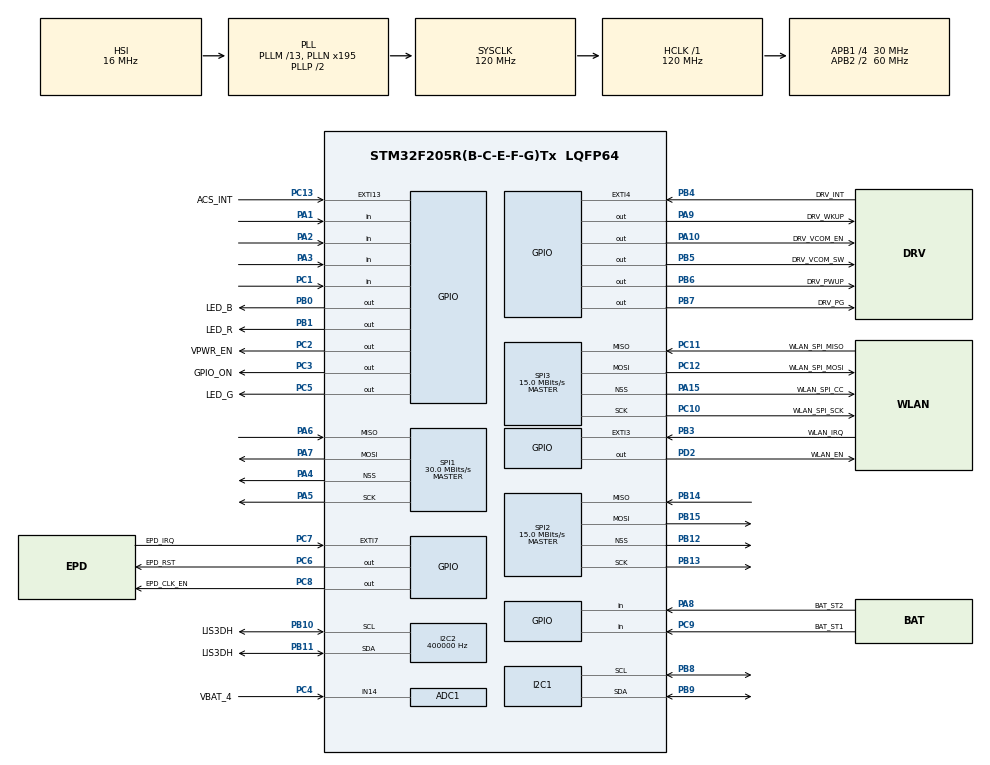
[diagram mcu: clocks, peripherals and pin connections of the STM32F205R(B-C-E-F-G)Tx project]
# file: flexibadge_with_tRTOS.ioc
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ADC1.Channel-4\#ChannelRegularConversion=ADC_CHANNEL_14
ADC1.NbrOfConversionFlag=1
ADC1.Rank-4\#ChannelRegularConversion=1
ADC1.SamplingTime-4\#ChannelRegularConversion=ADC_SAMPLETIME_3CYCLES
ADC1.master=1
Dma.Request0=SPI3_RX
Dma.Request1=SPI3_TX
Dma.SPI3_RX.0.Direction=DMA_PERIPH_TO_MEMORY
Dma.SPI3_RX.0.FIFOMode=DMA_FIFOMODE_DISABLE
Dma.SPI3_RX.0.Instance=DMA1_Stream0
Dma.SPI3_RX.0.MemDataAlignment=DMA_MDATAALIGN_BYTE
Dma.SPI3_RX.0.MemInc=DMA_MINC_ENABLE
Dma.SPI3_RX.0.Mode=DMA_NORMAL
Dma.SPI3_RX.0.PeriphDataAlignment=DMA_PDATAALIGN_BYTE
Dma.SPI3_RX.0.PeriphInc=DMA_PINC_DISABLE
Dma.SPI3_RX.0.Priority=DMA_PRIORITY_LOW
Dma.SPI3_TX.1.Direction=DMA_MEMORY_TO_PERIPH
Dma.SPI3_TX.1.FIFOMode=DMA_FIFOMODE_DISABLE
Dma.SPI3_TX.1.Instance=DMA1_Stream5
Dma.SPI3_TX.1.MemDataAlignment=DMA_MDATAALIGN_BYTE
Dma.SPI3_TX.1.MemInc=DMA_MINC_ENABLE
Dma.SPI3_TX.1.Mode=DMA_NORMAL
Dma.SPI3_TX.1.PeriphDataAlignment=DMA_PDATAALIGN_BYTE
Dma.SPI3_TX.1.PeriphInc=DMA_PINC_DISABLE
Dma.SPI3_TX.1.Priority=DMA_PRIORITY_LOW
FREERTOS.Tasks01=defaultTask,0,128,StartDefaultTask,Default,NULL,Dynamic,NULL,NULL;wifi,0,512,StartTask_wifi,Default,NULL,Dynamic,NULL,NULL
I2C2.ClockSpeed=400000
I2C2.I2C_Mode=I2C_Fast
Mcu.Family=STM32F2
Mcu.Name=STM32F205R(B-C-E-F-G)Tx
Mcu.Package=LQFP64
NVIC.DMA1_Stream0_IRQn=true\:5\:0\:false\:false\:true\:true
NVIC.DMA1_Stream5_IRQn=true\:5\:0\:false\:false\:true\:true
NVIC.EXTI15_10_IRQn=true\:5\:0\:false\:false\:true\:true
NVIC.EXTI3_IRQn=true\:5\:0\:false\:false\:true\:true
NVIC.I2C2_EV_IRQn=true\:5\:0\:false\:false\:true\:true
NVIC.PriorityGroup=NVIC_PRIORITYGROUP_4
NVIC.SPI1_IRQn=true\:5\:0\:false\:false\:true\:true
NVIC.TIM8_UP_TIM13_IRQn=true\:0\:0\:false\:false\:true\:false
NVIC.TimeBase=TIM8_UP_TIM13_IRQn
NVIC.TimeBaseIP=TIM8
PA0-WKUP.Mode=SYS_WakeUp0
PA0-WKUP.Signal=SYS_WKUP
PA1.Signal=GPIO_Input
PA10.GPIO_Label=DRV_VCOM_EN
PA10.Signal=GPIO_Output
PA13.Mode=Serial_Wire
PA13.Signal=SYS_JTMS-SWDIO
PA14.Mode=Serial_Wire
PA14.Signal=SYS_JTCK-SWCLK
PA15.GPIO_Label=WLAN_SPI_CC
PA15.Mode=NSS_Signal_Hard_Output
PA15.Signal=SPI3_NSS
PA2.Signal=GPIO_Input
PA3.Signal=GPIO_Input
PA4.Mode=NSS_Signal_Hard_Output
PA4.Signal=SPI1_NSS
PA5.Mode=Full_Duplex_Master
PA5.Signal=SPI1_SCK
PA6.Mode=Full_Duplex_Master
PA6.Signal=SPI1_MISO
PA7.Mode=Full_Duplex_Master
PA7.Signal=SPI1_MOSI
PA8.GPIO_Label=BAT_ST2
PA8.Signal=GPIO_Input
PA9.GPIO_Label=DRV_WKUP
PA9.Signal=GPIO_Output
PB0.GPIO_Label=LED_B
PB0.PinState=GPIO_PIN_SET
PB0.Signal=GPIO_Output
PB1.GPIO_Label=LED_R
PB1.PinState=GPIO_PIN_SET
PB1.Signal=GPIO_Output
PB10.GPIO_Label=LIS3DH
PB10.Mode=I2C
PB10.Signal=I2C2_SCL
PB11.GPIO_Label=LIS3DH
PB11.Mode=I2C
PB11.Signal=I2C2_SDA
PB12.Mode=NSS_Signal_Hard_Output
PB12.Signal=SPI2_NSS
PB13.Mode=Full_Duplex_Master
PB13.Signal=SPI2_SCK
PB14.Mode=Full_Duplex_Master
PB14.Signal=SPI2_MISO
PB15.Mode=Full_Duplex_Master
PB15.Signal=SPI2_MOSI
PB3.GPIO_Label=WLAN_IRQ
PB3.Signal=GPXTI3
PB4.GPIO_Label=DRV_INT
PB4.Signal=GPXTI4
PB5.GPIO_Label=DRV_VCOM_SW
PB5.Signal=GPIO_Output
PB6.GPIO_Label=DRV_PWUP
PB6.Signal=GPIO_Output
PB7.GPIO_Label=DRV_PG
PB7.Signal=GPIO_Output
PB8.Mode=I2C
PB8.Signal=I2C1_SCL
PB9.Mode=I2C
PB9.Signal=I2C1_SDA
PC1.Signal=GPIO_Input
PC10.GPIO_Label=WLAN_SPI_SCK
PC10.Mode=Full_Duplex_Master
PC10.Signal=SPI3_SCK
PC11.GPIO_Label=WLAN_SPI_MISO
PC11.Mode=Full_Duplex_Master
PC11.Signal=SPI3_MISO
PC12.GPIO_Label=WLAN_SPI_MOSI
PC12.Mode=Full_Duplex_Master
PC12.Signal=SPI3_MOSI
PC13.GPIO_Label=ACS_INT
PC13.Signal=GPXTI13
PC14-OSC32_IN.Mode=LSE-External-Oscillator
PC14-OSC32_IN.Signal=RCC_OSC32_IN
PC15-OSC32_OUT.Mode=LSE-External-Oscillator
PC15-OSC32_OUT.Signal=RCC_OSC32_OUT
PC2.GPIO_Label=VPWR_EN
PC2.PinState=GPIO_PIN_SET
PC2.Signal=GPIO_Output
PC3.GPIO_Label=GPIO_ON
PC3.Signal=GPIO_Output
PC4.GPIO_Label=VBAT_4
PC4.Signal=ADCx_IN14
PC5.GPIO_Label=LED_G
PC5.PinState=GPIO_PIN_SET
PC5.Signal=GPIO_Output
PC6.GPIO_Label=EPD_RST
PC6.Signal=GPIO_Output
PC7.GPIO_Label=EPD_IRQ
PC7.Signal=GPXTI7
PC8.GPIO_Label=EPD_CLK_EN
PC8.Signal=GPIO_Output
PC9.GPIO_Label=BAT_ST1
PC9.Signal=GPIO_Input
PD2.GPIO_Label=WLAN_EN
PD2.Signal=GPIO_Output
PH0-OSC_IN.Mode=HSE-External-Oscillator
PH0-OSC_IN.Signal=RCC_OSC_IN
PH1-OSC_OUT.Mode=HSE-External-Oscillator
PH1-OSC_OUT.Signal=RCC_OSC_OUT
ProjectManager.HeapSize=0x200
ProjectManager.StackSize=0x400
ProjectManager.TargetToolchain=TrueSTUDIO
RCC.48MHZClocksFreq_Value=48000000
RCC.AHBFreq_Value=120000000
RCC.APB1CLKDivider=RCC_HCLK_DIV4
RCC.APB1Freq_Value=30000000
RCC.APB1TimFreq_Value=60000000
RCC.APB2CLKDivider=RCC_HCLK_DIV2
RCC.APB2Freq_Value=60000000
RCC.APB2TimFreq_Value=120000000
RCC.CortexFreq_Value=120000000
RCC.HCLKFreq_Value=120000000
RCC.HSE_VALUE=16000000
RCC.HSI_VALUE=16000000
RCC.PLLM=13
RCC.PLLN=195
RCC.PLLQ=5
RCC.RCC_RTC_Clock_Source=RCC_RTCCLKSOURCE_LSE
RCC.RCC_RTC_Clock_SourceVirtual=RCC_RTCCLKSOURCE_LSE
RCC.RCC_RTC_Clock_Source_FROM_HSE=RCC_RTCCLKSOURCE_HSE_DIV31
RCC.SYSCLKFreq_VALUE=120000000
RCC.SYSCLKSource=RCC_SYSCLKSOURCE_PLLCLK
RCC.VCOOutputFreq_Value=240000000
SH.ADCx_IN14.0=ADC1_IN14,IN14
SPI1.BaudRatePrescaler=SPI_BAUDRATEPRESCALER_2
SPI1.CalculateBaudRate=30.0 MBits/s
SPI1.Mode=SPI_MODE_MASTER
SPI1.VirtualNSS=VM_NSSHARD
SPI1.VirtualType=VM_MASTER
SPI2.BaudRatePrescaler=SPI_BAUDRATEPRESCALER_2
SPI2.CalculateBaudRate=15.0 MBits/s
SPI2.Mode=SPI_MODE_MASTER
SPI2.VirtualNSS=VM_NSSHARD
SPI2.VirtualType=VM_MASTER
SPI3.BaudRatePrescaler=SPI_BAUDRATEPRESCALER_2
SPI3.CalculateBaudRate=15.0 MBits/s
SPI3.Mode=SPI_MODE_MASTER
SPI3.VirtualNSS=VM_NSSHARD
SPI3.VirtualType=VM_MASTER
VP_FREERTOS_VS_ENABLE.Mode=Enabled
VP_RTC_VS_RTC_Activate.Mode=RTC_Enabled
VP_SYS_VS_tim8.Mode=TIM8
board=flexibadge_with_tRTOS

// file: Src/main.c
/**
  ******************************************************************************
  * File Name          : main.c
  * Description        : Main program body
  ******************************************************************************
  * This notice applies to any and all portions of this file
  * that are not between comment pairs USER CODE BEGIN and
  * USER CODE END. Other portions of this file, whether
  * inserted by the user or by software development tools
  * are owned by their respective copyright owners.
  *
  * Copyright (c) 2017 STMicroelectronics International N.V.
  * All rights reserved.
  *
  * Redistribution and use in source and binary forms, with or without
  * modification, are permitted, provided that the following conditions are met:
  *
  * 1. Redistribution of source code must retain the above copyright notice,
  *    this list of conditions and the following disclaimer.
  * 2. Redistributions in binary form must reproduce the above copyright notice,
  *    this list of conditions and the following disclaimer in the documentation
  *    and/or other materials provided with the distribution.
  * 3. Neither the name of STMicroelectronics nor the names of other
  *    contributors to this software may be used to endorse or promote products
  *    derived from this software without specific written permission.
  * 4. This software, including modifications and/or derivative works of this
  *    software, must execute solely and exclusively on microcontroller or
  *    microprocessor devices manufactured by or for STMicroelectronics.
  * 5. Redistribution and use of this software other than as permitted under
  *    this license is void and will automatically terminate your rights under
  *    this license.
  *
  * THIS SOFTWARE IS PROVIDED BY STMICROELECTRONICS AND CONTRIBUTORS "AS IS"
  * AND ANY EXPRESS, IMPLIED OR STATUTORY WARRANTIES, INCLUDING, BUT NOT
  * LIMITED TO, THE IMPLIED WARRANTIES OF MERCHANTABILITY, FITNESS FOR A
  * PARTICULAR PURPOSE AND NON-INFRINGEMENT OF THIRD PARTY INTELLECTUAL PROPERTY
  * RIGHTS ARE DISCLAIMED TO THE FULLEST EXTENT PERMITTED BY LAW. IN NO EVENT
  * SHALL STMICROELECTRONICS OR CONTRIBUTORS BE LIABLE FOR ANY DIRECT, INDIRECT,
  * INCIDENTAL, SPECIAL, EXEMPLARY, OR CONSEQUENTIAL DAMAGES (INCLUDING, BUT NOT
  * LIMITED TO, PROCUREMENT OF SUBSTITUTE GOODS OR SERVICES; LOSS OF USE, DATA,
  * OR PROFITS; OR BUSINESS INTERRUPTION) HOWEVER CAUSED AND ON ANY THEORY OF
  * LIABILITY, WHETHER IN CONTRACT, STRICT LIABILITY, OR TORT (INCLUDING
  * NEGLIGENCE OR OTHERWISE) ARISING IN ANY WAY OUT OF THE USE OF THIS SOFTWARE,
  * EVEN IF ADVISED OF THE POSSIBILITY OF SUCH DAMAGE.
  *
  ******************************************************************************
  */
#include "main.h"
#include "stm32f2xx_hal.h"
#include "cmsis_os.h"

ADC_HandleTypeDef hadc1;

I2C_HandleTypeDef hi2c1;
I2C_HandleTypeDef hi2c2;

RTC_HandleTypeDef hrtc;

SPI_HandleTypeDef hspi1;
SPI_HandleTypeDef hspi2;
SPI_HandleTypeDef hspi3;
DMA_HandleTypeDef hdma_spi3_rx;
DMA_HandleTypeDef hdma_spi3_tx;

osThreadId defaultTaskHandle;
osThreadId wifiHandle;

/* USER CODE BEGIN PV */
/* Private variables ---------------------------------------------------------*/

/* USER CODE END PV */

void SystemClock_Config(void);
static void MX_GPIO_Init(void);
static void MX_DMA_Init(void);
static void MX_SPI1_Init(void);
static void MX_I2C2_Init(void);
static void MX_SPI2_Init(void);
static void MX_SPI3_Init(void);
static void MX_I2C1_Init(void);
static void MX_RTC_Init(void);
static void MX_ADC1_Init(void);
void StartDefaultTask(void const * argument);
void StartTask_wifi(void const * argument);

/* USER CODE BEGIN PFP */
/* Private function prototypes -----------------------------------------------*/

/* USER CODE END PFP */

int main(void)
{

  /* MCU Configuration----------------------------------------------------------*/

  /* Reset of all peripherals, Initializes the Flash interface and the Systick. */
  HAL_Init();

  /* Configure the system clock */
  SystemClock_Config();

  /* Initialize all configured peripherals */
  MX_GPIO_Init();
  MX_DMA_Init();
  MX_SPI1_Init();
  MX_I2C2_Init();
  MX_SPI2_Init();
  MX_SPI3_Init();
  MX_I2C1_Init();
  MX_RTC_Init();
  MX_ADC1_Init();

  /* Create the thread(s) */
  /* definition and creation of defaultTask */
  osThreadDef(defaultTask, StartDefaultTask, osPriorityNormal, 0, 128);
  defaultTaskHandle = osThreadCreate(osThread(defaultTask), NULL);

  /* definition and creation of wifi */
  osThreadDef(wifi, StartTask_wifi, osPriorityNormal, 0, 512);
  wifiHandle = osThreadCreate(osThread(wifi), NULL);

  /* Start scheduler */
  osKernelStart();

  /* We should never get here as control is now taken by the scheduler */

  /* Infinite loop */
  while (1)
  {

  }

}

/** System Clock Configuration
*/
void SystemClock_Config(void)
{

  RCC_OscInitTypeDef RCC_OscInitStruct;
  RCC_ClkInitTypeDef RCC_ClkInitStruct;
  RCC_PeriphCLKInitTypeDef PeriphClkInitStruct;

    /**Initializes the CPU, AHB and APB busses clocks
    */
  RCC_OscInitStruct.OscillatorType = RCC_OSCILLATORTYPE_HSI|RCC_OSCILLATORTYPE_LSE;
  RCC_OscInitStruct.LSEState = RCC_LSE_ON;
  RCC_OscInitStruct.HSIState = RCC_HSI_ON;
  RCC_OscInitStruct.HSICalibrationValue = 16;
  RCC_OscInitStruct.PLL.PLLState = RCC_PLL_ON;
  RCC_OscInitStruct.PLL.PLLSource = RCC_PLLSOURCE_HSI;
  RCC_OscInitStruct.PLL.PLLM = 13;
  RCC_OscInitStruct.PLL.PLLN = 195;
  RCC_OscInitStruct.PLL.PLLP = RCC_PLLP_DIV2;
  RCC_OscInitStruct.PLL.PLLQ = 5;
  if (HAL_RCC_OscConfig(&RCC_OscInitStruct) != HAL_OK)
  {
    _Error_Handler(__FILE__, __LINE__);
  }

    /**Initializes the CPU, AHB and APB busses clocks
    */
  RCC_ClkInitStruct.ClockType = RCC_CLOCKTYPE_HCLK|RCC_CLOCKTYPE_SYSCLK
                              |RCC_CLOCKTYPE_PCLK1|RCC_CLOCKTYPE_PCLK2;
  RCC_ClkInitStruct.SYSCLKSource = RCC_SYSCLKSOURCE_PLLCLK;
  RCC_ClkInitStruct.AHBCLKDivider = RCC_SYSCLK_DIV1;
  RCC_ClkInitStruct.APB1CLKDivider = RCC_HCLK_DIV4;
  RCC_ClkInitStruct.APB2CLKDivider = RCC_HCLK_DIV2;

  if (HAL_RCC_ClockConfig(&RCC_ClkInitStruct, FLASH_LATENCY_3) != HAL_OK)
  {
    _Error_Handler(__FILE__, __LINE__);
  }

  PeriphClkInitStruct.PeriphClockSelection = RCC_PERIPHCLK_RTC;
  PeriphClkInitStruct.RTCClockSelection = RCC_RTCCLKSOURCE_LSE;
  if (HAL_RCCEx_PeriphCLKConfig(&PeriphClkInitStruct) != HAL_OK)
  {
    _Error_Handler(__FILE__, __LINE__);
  }

    /**Configure the Systick interrupt time
    */
  HAL_SYSTICK_Config(HAL_RCC_GetHCLKFreq()/1000);

    /**Configure the Systick
    */
  HAL_SYSTICK_CLKSourceConfig(SYSTICK_CLKSOURCE_HCLK);

  /* SysTick_IRQn interrupt configuration */
  HAL_NVIC_SetPriority(SysTick_IRQn, 15, 0);
}

/* ADC1 init function */
static void MX_ADC1_Init(void)
{

  ADC_ChannelConfTypeDef sConfig;

    /**Configure the global features of the ADC (Clock, Resolution, Data Alignment and number of conversion)
    */
  hadc1.Instance = ADC1;
  hadc1.Init.ClockPrescaler = ADC_CLOCK_SYNC_PCLK_DIV2;
  hadc1.Init.Resolution = ADC_RESOLUTION_12B;
  hadc1.Init.ScanConvMode = DISABLE;
  hadc1.Init.ContinuousConvMode = DISABLE;
  hadc1.Init.DiscontinuousConvMode = DISABLE;
  hadc1.Init.ExternalTrigConvEdge = ADC_EXTERNALTRIGCONVEDGE_NONE;
  hadc1.Init.ExternalTrigConv = ADC_SOFTWARE_START;
  hadc1.Init.DataAlign = ADC_DATAALIGN_RIGHT;
  hadc1.Init.NbrOfConversion = 1;
  hadc1.Init.DMAContinuousRequests = DISABLE;
  hadc1.Init.EOCSelection = ADC_EOC_SINGLE_CONV;
  if (HAL_ADC_Init(&hadc1) != HAL_OK)
  {
    _Error_Handler(__FILE__, __LINE__);
  }

    /**Configure for the selected ADC regular channel its corresponding rank in the sequencer and its sample time.
    */
  sConfig.Channel = ADC_CHANNEL_14;
  sConfig.Rank = 1;
  sConfig.SamplingTime = ADC_SAMPLETIME_3CYCLES;
  if (HAL_ADC_ConfigChannel(&hadc1, &sConfig) != HAL_OK)
  {
    _Error_Handler(__FILE__, __LINE__);
  }

}

/* I2C1 init function */
static void MX_I2C1_Init(void)
{

  hi2c1.Instance = I2C1;
  hi2c1.Init.ClockSpeed = 100000;
  hi2c1.Init.DutyCycle = I2C_DUTYCYCLE_2;
  hi2c1.Init.OwnAddress1 = 0;
  hi2c1.Init.AddressingMode = I2C_ADDRESSINGMODE_7BIT;
  hi2c1.Init.DualAddressMode = I2C_DUALADDRESS_DISABLE;
  hi2c1.Init.OwnAddress2 = 0;
  hi2c1.Init.GeneralCallMode = I2C_GENERALCALL_DISABLE;
  hi2c1.Init.NoStretchMode = I2C_NOSTRETCH_DISABLE;
  if (HAL_I2C_Init(&hi2c1) != HAL_OK)
  {
    _Error_Handler(__FILE__, __LINE__);
  }

}

/* I2C2 init function */
static void MX_I2C2_Init(void)
{

  hi2c2.Instance = I2C2;
  hi2c2.Init.ClockSpeed = 400000;
  hi2c2.Init.DutyCycle = I2C_DUTYCYCLE_2;
  hi2c2.Init.OwnAddress1 = 0;
  hi2c2.Init.AddressingMode = I2C_ADDRESSINGMODE_7BIT;
  hi2c2.Init.DualAddressMode = I2C_DUALADDRESS_DISABLE;
  hi2c2.Init.OwnAddress2 = 0;
  hi2c2.Init.GeneralCallMode = I2C_GENERALCALL_DISABLE;
  hi2c2.Init.NoStretchMode = I2C_NOSTRETCH_DISABLE;
  if (HAL_I2C_Init(&hi2c2) != HAL_OK)
  {
    _Error_Handler(__FILE__, __LINE__);
  }

}

/* RTC init function */
static void MX_RTC_Init(void)
{

    /**Initialize RTC Only
    */
  hrtc.Instance = RTC;
  hrtc.Init.HourFormat = RTC_HOURFORMAT_24;
  hrtc.Init.AsynchPrediv = 127;
  hrtc.Init.SynchPrediv = 255;
  hrtc.Init.OutPut = RTC_OUTPUT_DISABLE;
  hrtc.Init.OutPutPolarity = RTC_OUTPUT_POLARITY_HIGH;
  hrtc.Init.OutPutType = RTC_OUTPUT_TYPE_OPENDRAIN;
  if (HAL_RTC_Init(&hrtc) != HAL_OK)
  {
    _Error_Handler(__FILE__, __LINE__);
  }

}

/* SPI1 init function */
static void MX_SPI1_Init(void)
{

  hspi1.Instance = SPI1;
  hspi1.Init.Mode = SPI_MODE_MASTER;
  hspi1.Init.Direction = SPI_DIRECTION_2LINES;
  hspi1.Init.DataSize = SPI_DATASIZE_8BIT;
  hspi1.Init.CLKPolarity = SPI_POLARITY_LOW;
  hspi1.Init.CLKPhase = SPI_PHASE_1EDGE;
  hspi1.Init.NSS = SPI_NSS_HARD_OUTPUT;
  hspi1.Init.BaudRatePrescaler = SPI_BAUDRATEPRESCALER_2;
  hspi1.Init.FirstBit = SPI_FIRSTBIT_MSB;
  hspi1.Init.TIMode = SPI_TIMODE_DISABLE;
  hspi1.Init.CRCCalculation = SPI_CRCCALCULATION_DISABLE;
  hspi1.Init.CRCPolynomial = 10;
  if (HAL_SPI_Init(&hspi1) != HAL_OK)
  {
    _Error_Handler(__FILE__, __LINE__);
  }

}

/* SPI2 init function */
static void MX_SPI2_Init(void)
{

  hspi2.Instance = SPI2;
  hspi2.Init.Mode = SPI_MODE_MASTER;
  hspi2.Init.Direction = SPI_DIRECTION_2LINES;
  hspi2.Init.DataSize = SPI_DATASIZE_8BIT;
  hspi2.Init.CLKPolarity = SPI_POLARITY_LOW;
  hspi2.Init.CLKPhase = SPI_PHASE_1EDGE;
  hspi2.Init.NSS = SPI_NSS_HARD_OUTPUT;
  hspi2.Init.BaudRatePrescaler = SPI_BAUDRATEPRESCALER_2;
  hspi2.Init.FirstBit = SPI_FIRSTBIT_MSB;
  hspi2.Init.TIMode = SPI_TIMODE_DISABLE;
  hspi2.Init.CRCCalculation = SPI_CRCCALCULATION_DISABLE;
  hspi2.Init.CRCPolynomial = 10;
  if (HAL_SPI_Init(&hspi2) != HAL_OK)
  {
    _Error_Handler(__FILE__, __LINE__);
  }

}

/* SPI3 init function */
static void MX_SPI3_Init(void)
{

  hspi3.Instance = SPI3;
  hspi3.Init.Mode = SPI_MODE_MASTER;
  hspi3.Init.Direction = SPI_DIRECTION_2LINES;
  hspi3.Init.DataSize = SPI_DATASIZE_8BIT;
  hspi3.Init.CLKPolarity = SPI_POLARITY_LOW;
  hspi3.Init.CLKPhase = SPI_PHASE_1EDGE;
  hspi3.Init.NSS = SPI_NSS_HARD_OUTPUT;
  hspi3.Init.BaudRatePrescaler = SPI_BAUDRATEPRESCALER_2;
  hspi3.Init.FirstBit = SPI_FIRSTBIT_MSB;
  hspi3.Init.TIMode = SPI_TIMODE_DISABLE;
  hspi3.Init.CRCCalculation = SPI_CRCCALCULATION_DISABLE;
  hspi3.Init.CRCPolynomial = 10;
  if (HAL_SPI_Init(&hspi3) != HAL_OK)
  {
    _Error_Handler(__FILE__, __LINE__);
  }

}

static void MX_DMA_Init(void)
{
  /* DMA controller clock enable */
  __HAL_RCC_DMA1_CLK_ENABLE();

  /* DMA interrupt init */
  /* DMA1_Stream0_IRQn interrupt configuration */
  HAL_NVIC_SetPriority(DMA1_Stream0_IRQn, 5, 0);
  HAL_NVIC_EnableIRQ(DMA1_Stream0_IRQn);
  /* DMA1_Stream5_IRQn interrupt configuration */
  HAL_NVIC_SetPriority(DMA1_Stream5_IRQn, 5, 0);
  HAL_NVIC_EnableIRQ(DMA1_Stream5_IRQn);

}

/** Configure pins as
        * Analog
        * Input
        * Output
        * EVENT_OUT
        * EXTI
*/
static void MX_GPIO_Init(void)
{

  GPIO_InitTypeDef GPIO_InitStruct;

  /* GPIO Ports Clock Enable */
  __HAL_RCC_GPIOC_CLK_ENABLE();
  __HAL_RCC_GPIOH_CLK_ENABLE();
  __HAL_RCC_GPIOA_CLK_ENABLE();
  __HAL_RCC_GPIOB_CLK_ENABLE();
  __HAL_RCC_GPIOD_CLK_ENABLE();

  /*Configure GPIO pin Output Level */
  HAL_GPIO_WritePin(GPIOC, VPWR_EN_Pin|LED_G_Pin, GPIO_PIN_SET);

  /*Configure GPIO pin Output Level */
  HAL_GPIO_WritePin(GPIOC, GPIO_ON_Pin|EPD_RST_Pin|EPD_CLK_EN_Pin, GPIO_PIN_RESET);

  /*Configure GPIO pin Output Level */
  HAL_GPIO_WritePin(GPIOB, LED_B_Pin|LED_R_Pin, GPIO_PIN_SET);

  /*Configure GPIO pin Output Level */
  HAL_GPIO_WritePin(GPIOA, DRV_WKUP_Pin|DRV_VCOM_EN_Pin, GPIO_PIN_RESET);

  /*Configure GPIO pin Output Level */
  HAL_GPIO_WritePin(WLAN_EN_GPIO_Port, WLAN_EN_Pin, GPIO_PIN_RESET);

  /*Configure GPIO pin Output Level */
  HAL_GPIO_WritePin(GPIOB, DRV_VCOM_SW_Pin|DRV_PWUP_Pin|DRV_PG_Pin, GPIO_PIN_RESET);

  /*Configure GPIO pins : ACS_INT_Pin EPD_IRQ_Pin */
  GPIO_InitStruct.Pin = ACS_INT_Pin|EPD_IRQ_Pin;
  GPIO_InitStruct.Mode = GPIO_MODE_IT_RISING;
  GPIO_InitStruct.Pull = GPIO_NOPULL;
  HAL_GPIO_Init(GPIOC, &GPIO_InitStruct);

  /*Configure GPIO pins : PC1 BAT_ST1_Pin */
  GPIO_InitStruct.Pin = GPIO_PIN_1|BAT_ST1_Pin;
  GPIO_InitStruct.Mode = GPIO_MODE_INPUT;
  GPIO_InitStruct.Pull = GPIO_NOPULL;
  HAL_GPIO_Init(GPIOC, &GPIO_InitStruct);

  /*Configure GPIO pins : VPWR_EN_Pin GPIO_ON_Pin LED_G_Pin EPD_RST_Pin
                           EPD_CLK_EN_Pin */
  GPIO_InitStruct.Pin = VPWR_EN_Pin|GPIO_ON_Pin|LED_G_Pin|EPD_RST_Pin
                          |EPD_CLK_EN_Pin;
  GPIO_InitStruct.Mode = GPIO_MODE_OUTPUT_PP;
  GPIO_InitStruct.Pull = GPIO_NOPULL;
  GPIO_InitStruct.Speed = GPIO_SPEED_FREQ_LOW;
  HAL_GPIO_Init(GPIOC, &GPIO_InitStruct);

  /*Configure GPIO pins : PA1 PA2 PA3 BAT_ST2_Pin */
  GPIO_InitStruct.Pin = GPIO_PIN_1|GPIO_PIN_2|GPIO_PIN_3|BAT_ST2_Pin;
  GPIO_InitStruct.Mode = GPIO_MODE_INPUT;
  GPIO_InitStruct.Pull = GPIO_NOPULL;
  HAL_GPIO_Init(GPIOA, &GPIO_InitStruct);

  /*Configure GPIO pins : LED_B_Pin LED_R_Pin DRV_VCOM_SW_Pin DRV_PWUP_Pin
                           DRV_PG_Pin */
  GPIO_InitStruct.Pin = LED_B_Pin|LED_R_Pin|DRV_VCOM_SW_Pin|DRV_PWUP_Pin
                          |DRV_PG_Pin;
  GPIO_InitStruct.Mode = GPIO_MODE_OUTPUT_PP;
  GPIO_InitStruct.Pull = GPIO_NOPULL;
  GPIO_InitStruct.Speed = GPIO_SPEED_FREQ_LOW;
  HAL_GPIO_Init(GPIOB, &GPIO_InitStruct);

  /*Configure GPIO pins : DRV_WKUP_Pin DRV_VCOM_EN_Pin */
  GPIO_InitStruct.Pin = DRV_WKUP_Pin|DRV_VCOM_EN_Pin;
  GPIO_InitStruct.Mode = GPIO_MODE_OUTPUT_PP;
  GPIO_InitStruct.Pull = GPIO_NOPULL;
  GPIO_InitStruct.Speed = GPIO_SPEED_FREQ_LOW;
  HAL_GPIO_Init(GPIOA, &GPIO_InitStruct);

  /*Configure GPIO pin : WLAN_EN_Pin */
  GPIO_InitStruct.Pin = WLAN_EN_Pin;
  GPIO_InitStruct.Mode = GPIO_MODE_OUTPUT_PP;
  GPIO_InitStruct.Pull = GPIO_NOPULL;
  GPIO_InitStruct.Speed = GPIO_SPEED_FREQ_LOW;
  HAL_GPIO_Init(WLAN_EN_GPIO_Port, &GPIO_InitStruct);

  /*Configure GPIO pins : WLAN_IRQ_Pin DRV_INT_Pin */
  GPIO_InitStruct.Pin = WLAN_IRQ_Pin|DRV_INT_Pin;
  GPIO_InitStruct.Mode = GPIO_MODE_IT_RISING;
  GPIO_InitStruct.Pull = GPIO_NOPULL;
  HAL_GPIO_Init(GPIOB, &GPIO_InitStruct);

  /* EXTI interrupt init*/
  HAL_NVIC_SetPriority(EXTI3_IRQn, 5, 0);
  HAL_NVIC_EnableIRQ(EXTI3_IRQn);

  HAL_NVIC_SetPriority(EXTI15_10_IRQn, 5, 0);
  HAL_NVIC_EnableIRQ(EXTI15_10_IRQn);

}

/* StartDefaultTask function */
void StartDefaultTask(void const * argument)
{

  /* USER CODE BEGIN 5 */
  /* Infinite loop */
  for(;;)
  {
    osDelay(100);
    HAL_GPIO_TogglePin(LED_G_GPIO_Port, LED_G_Pin);
  }
  /* USER CODE END 5 */
}

/* StartTask_wifi function */
void StartTask_wifi(void const * argument)
{
  for(;;)
  {
    osDelay(1);
  }
}

void HAL_TIM_PeriodElapsedCallback(TIM_HandleTypeDef *htim)
{
  if (htim->Instance == TIM8) {
    HAL_IncTick();
  }
}

void _Error_Handler(char * file, int line)
{
  while(1)
  {
  }
}

/************************ (C) COPYRIGHT STMicroelectronics *****END OF FILE****/
